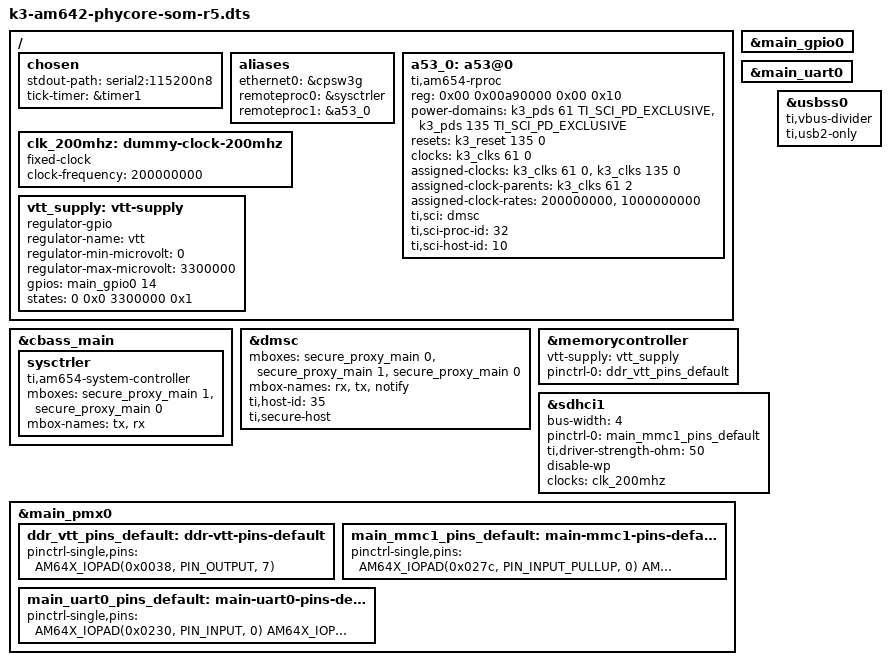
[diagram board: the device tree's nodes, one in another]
// SPDX-License-Identifier: GPL-2.0
/*
 * Copyright (C) 2021 PHYTEC America, LLC - https://www.phytec.com
 */

/dts-v1/;

#include "k3-am642-phycore-som.dts"
#include "k3-am64-phycore-som-ddr4.dtsi"
#include "k3-am64-ddr.dtsi"

/ {
	chosen {
		stdout-path = "serial2:115200n8";
		tick-timer = &timer1;
	};

	aliases {
		ethernet0 = &cpsw3g;
		remoteproc0 = &sysctrler;
		remoteproc1 = &a53_0;
	};

	a53_0: a53@0 {
		compatible = "ti,am654-rproc";
		reg = <0x00 0x00a90000 0x00 0x10>;
		power-domains = <&k3_pds 61 TI_SCI_PD_EXCLUSIVE>,
				<&k3_pds 135 TI_SCI_PD_EXCLUSIVE>;
		resets = <&k3_reset 135 0>;
		clocks = <&k3_clks 61 0>;
		assigned-clocks = <&k3_clks 61 0>, <&k3_clks 135 0>;
		assigned-clock-parents = <&k3_clks 61 2>;
		assigned-clock-rates = <200000000>, <1000000000>;
		ti,sci = <&dmsc>;
		ti,sci-proc-id = <32>;
		ti,sci-host-id = <10>;
		u-boot,dm-spl;
	};

	clk_200mhz: dummy-clock-200mhz {
		compatible = "fixed-clock";
		#clock-cells = <0>;
		clock-frequency = <200000000>;
		u-boot,dm-spl;
	};

	vtt_supply: vtt-supply {
		compatible = "regulator-gpio";
		regulator-name = "vtt";
		regulator-min-microvolt = <0>;
		regulator-max-microvolt = <3300000>;
		gpios = <&main_gpio0 14 GPIO_ACTIVE_HIGH>;
		states = <0 0x0 3300000 0x1>;
		u-boot,dm-spl;
	};
};

&cbass_main {
	sysctrler: sysctrler {
		compatible = "ti,am654-system-controller";
		mboxes = <&secure_proxy_main 1>,
			 <&secure_proxy_main 0>;
		mbox-names = "tx", "rx";
		u-boot,dm-spl;
	};
};

&dmsc {
	mboxes = <&secure_proxy_main 0>,
		 <&secure_proxy_main 1>,
		 <&secure_proxy_main 0>;
	mbox-names = "rx", "tx", "notify";
	ti,host-id = <35>;
	ti,secure-host;
};

&main_gpio0 {
	/delete-property/ power-domains;
};

&main_uart0 {
	/delete-property/ power-domains;
	/delete-property/ clocks;
	/delete-property/ clock-names;
};

&memorycontroller {
	vtt-supply = <&vtt_supply>;
	pinctrl-names = "default";
	pinctrl-0 = <&ddr_vtt_pins_default>;
};

&sdhci1 {
	status = "okay";
	pinctrl-names = "default";
	bus-width = <4>;
	pinctrl-0 = <&main_mmc1_pins_default>;
	ti,driver-strength-ohm = <50>;
	disable-wp;

	/delete-property/ power-domains;
	clocks = <&clk_200mhz>;
	clock-names = "clk_xin";
};

&usbss0 {
	status = "okay";
	ti,vbus-divider;
	ti,usb2-only;
};

&main_pmx0 {
	ddr_vtt_pins_default: ddr-vtt-pins-default {
		u-boot,dm-spl;
		pinctrl-single,pins = <
			AM64X_IOPAD(0x0038, PIN_OUTPUT, 7)	/* (L17) OSPI0_CSn3.GPIO0_14 */
		>;
	};

	main_mmc1_pins_default: main-mmc1-pins-default {
		pinctrl-single,pins = <
			AM64X_IOPAD(0x027c, PIN_INPUT_PULLUP, 0)	/* (K18) MMC1_DAT3 */
			AM64X_IOPAD(0x0280, PIN_INPUT_PULLUP, 0)	/* (K19) MMC1_DAT2 */
			AM64X_IOPAD(0x0284, PIN_INPUT_PULLUP, 0)	/* (L21) MMC1_DAT1 */
			AM64X_IOPAD(0x0288, PIN_INPUT_PULLUP, 0)	/* (K21) MMC1_DAT0 */
			AM64X_IOPAD(0x028c, PIN_INPUT_PULLDOWN, 0)	/* (L20) MMC1_CLK */
			AM64X_IOPAD(0x0290, PIN_INPUT, 0)		/* MMC1_CLKLB */
			AM64X_IOPAD(0x0294, PIN_INPUT_PULLUP, 0)	/* (J19) MMC1_CMD */
			AM64X_IOPAD(0x0298, PIN_INPUT, 0)		/* (D19) MMC1_SDCD */
		>;
	};

	main_uart0_pins_default: main-uart0-pins-default {
		pinctrl-single,pins = <
			AM64X_IOPAD(0x0230, PIN_INPUT, 0)	/* (D15) UART0_RXD */
			AM64X_IOPAD(0x0234, PIN_OUTPUT, 0)	/* (C16) UART0_TXD */
		>;
	};
};

#include "k3-am642-phycore-som-u-boot.dtsi"
